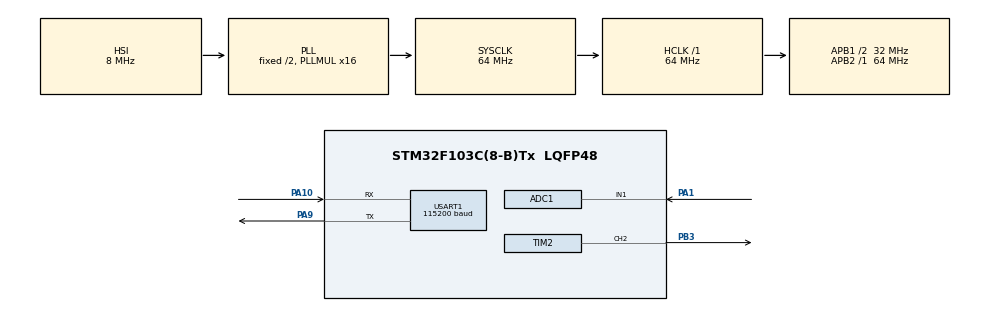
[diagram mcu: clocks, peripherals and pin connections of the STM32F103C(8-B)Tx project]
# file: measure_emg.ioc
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ADC1.Channel-13\#ChannelRegularConversion=ADC_CHANNEL_1
ADC1.ExternalTrigConv=ADC_EXTERNALTRIGCONV_T2_CC2
ADC1.NbrOfConversionFlag=1
ADC1.Rank-13\#ChannelRegularConversion=1
ADC1.SamplingTime-13\#ChannelRegularConversion=ADC_SAMPLETIME_1CYCLE_5
ADC1.master=1
Dma.ADC1.0.Direction=DMA_PERIPH_TO_MEMORY
Dma.ADC1.0.Instance=DMA1_Channel1
Dma.ADC1.0.MemDataAlignment=DMA_MDATAALIGN_HALFWORD
Dma.ADC1.0.MemInc=DMA_MINC_ENABLE
Dma.ADC1.0.Mode=DMA_NORMAL
Dma.ADC1.0.PeriphDataAlignment=DMA_PDATAALIGN_HALFWORD
Dma.ADC1.0.PeriphInc=DMA_PINC_DISABLE
Dma.ADC1.0.Priority=DMA_PRIORITY_LOW
Dma.Request0=ADC1
Mcu.Family=STM32F1
Mcu.Name=STM32F103C(8-B)Tx
Mcu.Package=LQFP48
NVIC.DMA1_Channel1_IRQn=true\:0\:0\:false\:false\:true\:false\:true\:true
NVIC.PriorityGroup=NVIC_PRIORITYGROUP_4
NVIC.TIM2_IRQn=true\:0\:0\:false\:false\:true\:true\:true\:true
PA1.Signal=ADCx_IN1
PA10.Mode=Asynchronous
PA10.Signal=USART1_RX
PA13.Mode=Serial_Wire
PA13.Signal=SYS_JTMS-SWDIO
PA14.Mode=Serial_Wire
PA14.Signal=SYS_JTCK-SWCLK
PA9.Mode=Asynchronous
PA9.Signal=USART1_TX
PB3.Signal=S_TIM2_CH2
ProjectManager.HeapSize=0x200
ProjectManager.StackSize=0x400
ProjectManager.TargetToolchain=MDK-ARM V5.32
RCC.ADCPresc=RCC_ADCPCLK2_DIV8
RCC.AHBFreq_Value=64000000
RCC.APB1CLKDivider=RCC_HCLK_DIV2
RCC.APB1Freq_Value=32000000
RCC.APB1TimFreq_Value=64000000
RCC.APB2Freq_Value=64000000
RCC.APB2TimFreq_Value=64000000
RCC.HCLKFreq_Value=64000000
RCC.PLLMUL=RCC_PLL_MUL16
RCC.SYSCLKFreq_VALUE=64000000
RCC.SYSCLKSource=RCC_SYSCLKSOURCE_PLLCLK
RCC.USBFreq_Value=64000000
SH.ADCx_IN1.0=ADC1_IN1,IN1
SH.S_TIM2_CH2.0=TIM2_CH2,PWM Generation2 CH2
TIM2.Channel-PWM\ Generation2\ CH2=TIM_CHANNEL_2
TIM2.Period=999
TIM2.Prescaler=63
TIM2.Pulse-PWM\ Generation2\ CH2=500
USART1.BaudRate=115200
USART1.VirtualMode=VM_ASYNC
VP_TIM2_VS_ClockSourceINT.Mode=Internal
board=custom

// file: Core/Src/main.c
/* USER CODE BEGIN Header */
/**
  ******************************************************************************
  * @file           : main.c
  * @brief          : Main program body
  ******************************************************************************
  * @attention
  *
  * Copyright (c) 2025 STMicroelectronics.
  * All rights reserved.
  *
  * This software is licensed under terms that can be found in the LICENSE file
  * in the root directory of this software component.
  * If no LICENSE file comes with this software, it is provided AS-IS.
  *
  ******************************************************************************
  */
/* USER CODE END Header */
#include "main.h"
#include "adc.h"
#include "dma.h"
#include "tim.h"
#include "usart.h"
#include "gpio.h"

/* USER CODE BEGIN Includes */
#include "stdio.h"

/* USER CODE END Includes */

void SystemClock_Config(void);

/* USER CODE BEGIN 0 */
float voltage[6]={0};
uint32_t adc_v[1200]={0};
/* USER CODE END 0 */

int main(void)
{

  /* MCU Configuration--------------------------------------------------------*/

  /* Reset of all peripherals, Initializes the Flash interface and the Systick. */
  HAL_Init();

  /* Configure the system clock */
  SystemClock_Config();

  /* Initialize all configured peripherals */
  MX_GPIO_Init();
  MX_DMA_Init();
  MX_TIM2_Init();
  MX_USART1_UART_Init();
  MX_ADC1_Init();
  /* USER CODE BEGIN 2 */
	HAL_TIM_PWM_Start(&htim2,TIM_CHANNEL_2); //开启定时器PWM模式
	HAL_ADC_Start_DMA(&hadc1, (uint32_t*)adc_v, 1);
//	HAL_ADC_Start(&hadc1);  //启动ADC转换
	HAL_Delay(100);
//	printf("okokokok");
  /* USER CODE END 2 */

  /* Infinite loop */
  while (1)
  {

    /* USER CODE BEGIN 3 */
//			HAL_ADC_Start(&hadc1);
//			adc_v[0]=HAL_ADC_GetValue(&hadc1);
//			printf("%d\n",adc_v[0]);

  }
  /* USER CODE END 3 */
}

void SystemClock_Config(void)
{
  RCC_OscInitTypeDef RCC_OscInitStruct = {0};
  RCC_ClkInitTypeDef RCC_ClkInitStruct = {0};
  RCC_PeriphCLKInitTypeDef PeriphClkInit = {0};

  /** Initializes the RCC Oscillators according to the specified parameters
  * in the RCC_OscInitTypeDef structure.
  */
  RCC_OscInitStruct.OscillatorType = RCC_OSCILLATORTYPE_HSI;
  RCC_OscInitStruct.HSIState = RCC_HSI_ON;
  RCC_OscInitStruct.HSICalibrationValue = RCC_HSICALIBRATION_DEFAULT;
  RCC_OscInitStruct.PLL.PLLState = RCC_PLL_ON;
  RCC_OscInitStruct.PLL.PLLSource = RCC_PLLSOURCE_HSI_DIV2;
  RCC_OscInitStruct.PLL.PLLMUL = RCC_PLL_MUL16;
  if (HAL_RCC_OscConfig(&RCC_OscInitStruct) != HAL_OK)
  {
    Error_Handler();
  }

  /** Initializes the CPU, AHB and APB buses clocks
  */
  RCC_ClkInitStruct.ClockType = RCC_CLOCKTYPE_HCLK|RCC_CLOCKTYPE_SYSCLK
                              |RCC_CLOCKTYPE_PCLK1|RCC_CLOCKTYPE_PCLK2;
  RCC_ClkInitStruct.SYSCLKSource = RCC_SYSCLKSOURCE_PLLCLK;
  RCC_ClkInitStruct.AHBCLKDivider = RCC_SYSCLK_DIV1;
  RCC_ClkInitStruct.APB1CLKDivider = RCC_HCLK_DIV2;
  RCC_ClkInitStruct.APB2CLKDivider = RCC_HCLK_DIV1;

  if (HAL_RCC_ClockConfig(&RCC_ClkInitStruct, FLASH_LATENCY_2) != HAL_OK)
  {
    Error_Handler();
  }
  PeriphClkInit.PeriphClockSelection = RCC_PERIPHCLK_ADC;
  PeriphClkInit.AdcClockSelection = RCC_ADCPCLK2_DIV8;
  if (HAL_RCCEx_PeriphCLKConfig(&PeriphClkInit) != HAL_OK)
  {
    Error_Handler();
  }
}

/* USER CODE BEGIN 4 */
void HAL_ADC_ConvCpltCallback(ADC_HandleTypeDef* hadc)
{
  if(hadc->Instance == ADC1)
  {
    for(int i=0; i<1; i++) printf("%d\n", adc_v[i]);
		HAL_ADC_Start_DMA(&hadc1, (uint32_t*)adc_v, 1);
  }
}
/* USER CODE END 4 */

void Error_Handler(void)
{
  __disable_irq();
  while (1)
  {
  }
}
